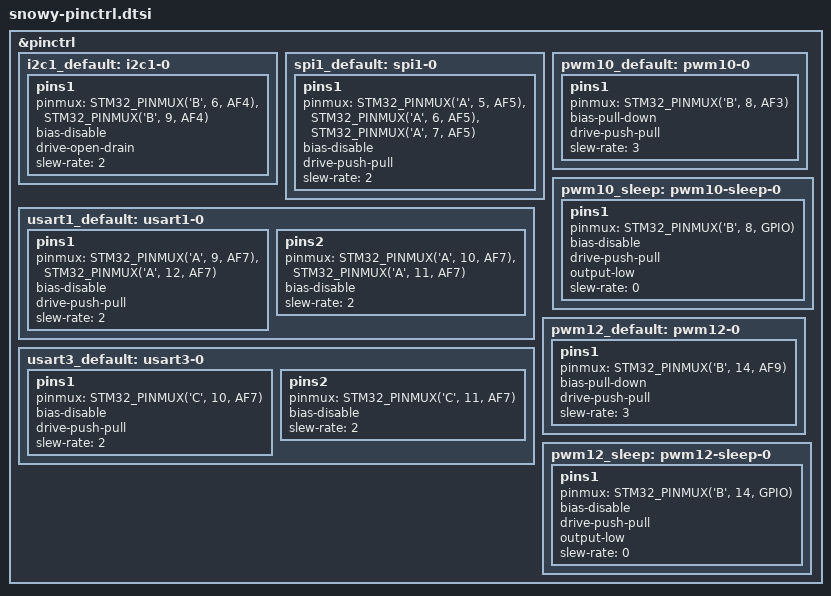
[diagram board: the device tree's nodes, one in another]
// SPDX-FileCopyrightText: 2026 Yusuf Sevim
// SPDX-License-Identifier: (GPL-2.0-only OR BSD-2-Clause)

&pinctrl {
	// External pull-ups
	i2c1_default: i2c1-0 {
		pins1 {
			pinmux = <STM32_PINMUX('B', 6, AF4)>, /* I2C1_SCL */
				 <STM32_PINMUX('B', 9, AF4)>; /* I2C1_SDA */
			bias-disable;
			drive-open-drain;
			slew-rate = <2>;
		};
	};

	spi1_default: spi1-0 {
		pins1 {
			pinmux = <STM32_PINMUX('A', 5, AF5)>, /* SPI1_SCK */
				 <STM32_PINMUX('A', 6, AF5)>, /* SPI1_MISO */
				 <STM32_PINMUX('A', 7, AF5)>; /* SPI1_MOSI */
			bias-disable;
			drive-push-pull;
			slew-rate = <2>;
		};
	};

	usart1_default: usart1-0 {
		pins1 {
			pinmux = <STM32_PINMUX('A', 9, AF7)>, /* USART1_TX */
				 <STM32_PINMUX('A', 12, AF7)>; /* USART1_RTS */
			bias-disable;
			drive-push-pull;
			slew-rate = <2>;
		};

		pins2 {
			pinmux = <STM32_PINMUX('A', 10, AF7)>, /* USART1_RX */
				 <STM32_PINMUX('A', 11, AF7)>; /* USART1_CTS */
			bias-disable;
			slew-rate = <2>;
		};
	};

	usart3_default: usart3-0 {
		pins1 {
			pinmux = <STM32_PINMUX('C', 10, AF7)>; /* USART3_TX */
			bias-disable;
			drive-push-pull;
			slew-rate = <2>;
		};

		pins2 {
			pinmux = <STM32_PINMUX('C', 11, AF7)>; /* USART3_RX */
			bias-disable;
			slew-rate = <2>;
		};
	};

	pwm10_default: pwm10-0 {
		pins1 {
			pinmux = <STM32_PINMUX('B', 8, AF3)>; /* TIM10_CH1 */
			bias-pull-down;
			drive-push-pull;
			slew-rate = <3>;
		};
	};

	pwm10_sleep: pwm10-sleep-0 {
		pins1 {
			pinmux = <STM32_PINMUX('B', 8, GPIO)>;
			bias-disable;
			drive-push-pull;
			output-low;
			slew-rate = <0>;
		};
	};

	pwm12_default: pwm12-0 {
		pins1 {
			pinmux = <STM32_PINMUX('B', 14, AF9)>; /* TIM12_CH1 */
			bias-pull-down;
			drive-push-pull;
			slew-rate = <3>;
		};
	};

	pwm12_sleep: pwm12-sleep-0 {
		pins1 {
			pinmux = <STM32_PINMUX('B', 14, GPIO)>;
			bias-disable;
			drive-push-pull;
			output-low;
			slew-rate = <0>;
		};
	};
};
